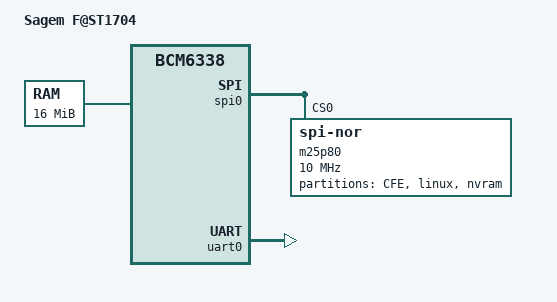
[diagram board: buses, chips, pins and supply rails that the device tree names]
/dts-v1/;

#include "bcm6338.dtsi"

/ {
	compatible = "sagem,f@st1704", "brcm,bcm6338";
	model = "Sagem F@ST1704";

	memory@0 {
		device_type = "memory";
		reg = <0x00000000 0x01000000>;
	};

	chosen {
		bootargs = "earlycon";
		stdout-path = "uart0:115200";
	};
};

&spi0 {
	status = "okay";

	m25p80@0 {
		#address-cells = <1>;
		#size-cells = <1>;
		compatible = "jedec,spi-nor";
		reg = <0>;
		linux,modalias = "m25p80", "mx25l12805d";
		spi-max-frequency = <10000000>;

		partitions {
			cfe@0 {
				label = "CFE";
				reg = <0x000000 0x010000>;
				read-only;
			};
			linux@10000 {
				label = "linux";
				reg = <0x010000 0x3e0000>;
				read-only;
			};
			nvram@3f0000 {
				label = "nvram";
				reg = <0x3f0000 0x010000>;
				read-only;
			};
		};
	};
};

&uart0 {
	status = "ok";
};
